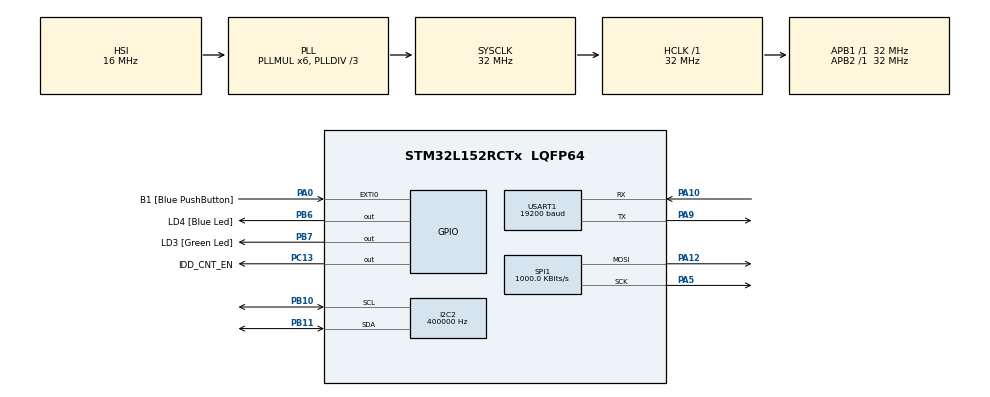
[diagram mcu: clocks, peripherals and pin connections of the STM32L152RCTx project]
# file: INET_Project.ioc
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I2C2.ClockSpeed=400000
I2C2.DutyCycle=I2C_DUTYCYCLE_2
I2C2.I2C_Mode=I2C_Fast
Mcu.Family=STM32L1
Mcu.Name=STM32L152RCTx
Mcu.Package=LQFP64
NVIC.PriorityGroup=NVIC_PRIORITYGROUP_0
PA0-WKUP1.GPIO_Label=B1 [Blue PushButton]
PA0-WKUP1.GPIO_ModeDefaultEXTI=GPIO_MODE_EVT_RISING
PA0-WKUP1.GPIO_PuPd=GPIO_NOPULL
PA0-WKUP1.Signal=GPXTI0
PA1.GPIO_Label=SEG0 [GH08172T_SEG0]
PA1.GPIO_Mode=GPIO_MODE_AF_PP
PA1.GPIO_PuPd=GPIO_NOPULL
PA1.GPIO_Speed=GPIO_SPEED_FREQ_LOW
PA1.Signal=LCD_SEG0
PA10.Mode=Asynchronous
PA10.Signal=USART1_RX
PA12.Mode=TX_Only_Simplex_Unidirect_Master
PA12.Signal=SPI1_MOSI
PA13.GPIO_Label=SWDIO
PA13.Signal=SYS_JTMS-SWDIO
PA14.GPIO_Label=SWCLK
PA14.Signal=SYS_JTCK-SWCLK
PA15.GPIO_Label=SEG12 [GH08172T_SEG12]
PA15.GPIO_Mode=GPIO_MODE_AF_PP
PA15.GPIO_PuPd=GPIO_NOPULL
PA15.GPIO_Speed=GPIO_SPEED_FREQ_LOW
PA15.Signal=LCD_SEG17
PA2.GPIO_Label=SEG1 [GH08172T_SEG1]
PA2.GPIO_Mode=GPIO_MODE_AF_PP
PA2.GPIO_PuPd=GPIO_NOPULL
PA2.GPIO_Speed=GPIO_SPEED_FREQ_LOW
PA2.Signal=LCD_SEG1
PA3.GPIO_Label=SEG2 [GH08172T_SEG2]
PA3.GPIO_Mode=GPIO_MODE_AF_PP
PA3.GPIO_PuPd=GPIO_NOPULL
PA3.GPIO_Speed=GPIO_SPEED_FREQ_LOW
PA3.Signal=LCD_SEG2
PA4.GPIO_Label=IDD_Measurement
PA4.GPIO_Mode=GPIO_MODE_ANALOG
PA4.GPIO_PuPd=GPIO_NOPULL
PA4.Signal=ADC_IN4
PA5.Mode=TX_Only_Simplex_Unidirect_Master
PA5.Signal=SPI1_SCK
PA6.GPIO_Label=GRP2_Sampling [Touch_Slider_1]
PA6.Signal=TS_G2_IO1
PA7.GPIO_Label=GRP2_Ground [Touch_Slider_1]
PA7.Signal=TS_G2_IO2
PA8.GPIO_Label=COM0 [GH08172T_COM0]
PA8.GPIO_Mode=GPIO_MODE_AF_PP
PA8.GPIO_PuPd=GPIO_NOPULL
PA8.GPIO_Speed=GPIO_SPEED_FREQ_LOW
PA8.Signal=LCD_COM0
PA9.Mode=Asynchronous
PA9.Signal=USART1_TX
PB0.GPIO_Label=GRP3_Sampling [Touch_Slider_3]
PB0.Signal=TS_G3_IO1
PB1.GPIO_Label=GRP3_Ground [Touch_Slider_3]
PB1.Signal=TS_G3_IO2
PB10.Mode=I2C
PB10.Signal=I2C2_SCL
PB11.Mode=I2C
PB11.Signal=I2C2_SDA
PB12.GPIO_Label=SEG8 [GH08172T_SEG8]
PB12.GPIO_Mode=GPIO_MODE_AF_PP
PB12.GPIO_PuPd=GPIO_NOPULL
PB12.GPIO_Speed=GPIO_SPEED_FREQ_LOW
PB12.Signal=LCD_SEG12
PB13.GPIO_Label=SEG9 [GH08172T_SEG9]
PB13.GPIO_Mode=GPIO_MODE_AF_PP
PB13.GPIO_PuPd=GPIO_NOPULL
PB13.GPIO_Speed=GPIO_SPEED_FREQ_LOW
PB13.Signal=LCD_SEG13
PB14.GPIO_Label=SEG10 [GH08172T_SEG10]
PB14.GPIO_Mode=GPIO_MODE_AF_PP
PB14.GPIO_PuPd=GPIO_NOPULL
PB14.GPIO_Speed=GPIO_SPEED_FREQ_LOW
PB14.Signal=LCD_SEG14
PB15.GPIO_Label=SEG11 [GH08172T_SEG11]
PB15.GPIO_Mode=GPIO_MODE_AF_PP
PB15.GPIO_PuPd=GPIO_NOPULL
PB15.GPIO_Speed=GPIO_SPEED_FREQ_LOW
PB15.Signal=LCD_SEG15
PB3.GPIO_Label=SEG3 [GH08172T_SEG3]
PB3.GPIO_Mode=GPIO_MODE_AF_PP
PB3.GPIO_PuPd=GPIO_NOPULL
PB3.GPIO_Speed=GPIO_SPEED_FREQ_LOW
PB3.Signal=LCD_SEG7
PB4.GPIO_Label=SEG4 [GH08172T_SEG4]
PB4.GPIO_Mode=GPIO_MODE_AF_PP
PB4.GPIO_PuPd=GPIO_NOPULL
PB4.GPIO_Speed=GPIO_SPEED_FREQ_LOW
PB4.Signal=LCD_SEG8
PB5.Signal=I2C1_SMBA
PB6.GPIO_Label=LD4 [Blue Led]
PB6.GPIO_ModeDefaultOutputPP=GPIO_MODE_OUTPUT_PP
PB6.GPIO_PuPd=GPIO_NOPULL
PB6.GPIO_Speed=GPIO_SPEED_FREQ_LOW
PB6.Signal=GPIO_Output
PB7.GPIO_Label=LD3 [Green Led]
PB7.GPIO_ModeDefaultOutputPP=GPIO_MODE_OUTPUT_PP
PB7.GPIO_PuPd=GPIO_NOPULL
PB7.GPIO_Speed=GPIO_SPEED_FREQ_LOW
PB7.Signal=GPIO_Output
PB8.GPIO_Label=SEG13 [GH08172T_SEG13]
PB8.GPIO_Mode=GPIO_MODE_AF_PP
PB8.GPIO_PuPd=GPIO_NOPULL
PB8.GPIO_Speed=GPIO_SPEED_FREQ_LOW
PB8.Signal=LCD_SEG16
PB9.GPIO_Label=COM3 [GH08172T_COM3]
PB9.GPIO_Mode=GPIO_MODE_AF_PP
PB9.GPIO_PuPd=GPIO_NOPULL
PB9.GPIO_Speed=GPIO_SPEED_FREQ_LOW
PB9.Signal=LCD_COM3
PC0.GPIO_Label=SEG14 [GH08172T_SEG14]
PC0.GPIO_Mode=GPIO_MODE_AF_PP
PC0.GPIO_PuPd=GPIO_NOPULL
PC0.GPIO_Speed=GPIO_SPEED_FREQ_LOW
PC0.Signal=LCD_SEG18
PC1.GPIO_Label=SEG15 [GH08172T_SEG15]
PC1.GPIO_Mode=GPIO_MODE_AF_PP
PC1.GPIO_PuPd=GPIO_NOPULL
PC1.GPIO_Speed=GPIO_SPEED_FREQ_LOW
PC1.Signal=LCD_SEG19
PC10.GPIO_Label=SEG22 [GH08172T_SEG22]
PC10.GPIO_Mode=GPIO_MODE_AF_PP
PC10.GPIO_PuPd=GPIO_NOPULL
PC10.GPIO_Speed=GPIO_SPEED_FREQ_LOW
PC10.Signal=LCD_SEG28
PC11.GPIO_Label=SEG23 [GH08172T_SEG23]
PC11.GPIO_Mode=GPIO_MODE_AF_PP
PC11.GPIO_PuPd=GPIO_NOPULL
PC11.GPIO_Speed=GPIO_SPEED_FREQ_LOW
PC11.Signal=LCD_SEG29
PC13-WKUP2.GPIO_Label=IDD_CNT_EN
PC13-WKUP2.Signal=GPIO_Output
PC14-OSC32_IN.GPIO_Label=PC14-OSC32_IN
PC14-OSC32_IN.Signal=RCC_OSC32_IN
PC15-OSC32_OUT.GPIO_Label=PC15-OSC32_OUT
PC15-OSC32_OUT.Signal=RCC_OSC32_OUT
PC2.GPIO_Label=SEG16 [GH08172T_SEG16]
PC2.GPIO_Mode=GPIO_MODE_AF_PP
PC2.GPIO_PuPd=GPIO_NOPULL
PC2.GPIO_Speed=GPIO_SPEED_FREQ_LOW
PC2.Signal=LCD_SEG20
PC3.GPIO_Label=SEG17 [GH08172T_SEG17]
PC3.GPIO_Mode=GPIO_MODE_AF_PP
PC3.GPIO_PuPd=GPIO_NOPULL
PC3.GPIO_Speed=GPIO_SPEED_FREQ_LOW
PC3.Signal=LCD_SEG21
PC4.GPIO_Label=GRP9_Sampling [Touch_Slider_2]
PC4.Signal=TS_G9_IO1
PC5.GPIO_Label=GRP9_Ground [Touch_Slider_2]
PC5.Signal=TS_G9_IO2
PC6.GPIO_Label=SEG18 [GH08172T_SEG18]
PC6.GPIO_Mode=GPIO_MODE_AF_PP
PC6.GPIO_PuPd=GPIO_NOPULL
PC6.GPIO_Speed=GPIO_SPEED_FREQ_LOW
PC6.Signal=LCD_SEG24
PC7.GPIO_Label=SEG19 [GH08172T_SEG19]
PC7.GPIO_Mode=GPIO_MODE_AF_PP
PC7.GPIO_PuPd=GPIO_NOPULL
PC7.GPIO_Speed=GPIO_SPEED_FREQ_LOW
PC7.Signal=LCD_SEG25
PC8.GPIO_Label=SEG20 [GH08172T_SEG20]
PC8.GPIO_Mode=GPIO_MODE_AF_PP
PC8.GPIO_PuPd=GPIO_NOPULL
PC8.GPIO_Speed=GPIO_SPEED_FREQ_LOW
PC8.Signal=LCD_SEG26
PC9.GPIO_Label=SEG21 [GH08172T_SEG21]
PC9.GPIO_Mode=GPIO_MODE_AF_PP
PC9.GPIO_PuPd=GPIO_NOPULL
PC9.GPIO_Speed=GPIO_SPEED_FREQ_LOW
PC9.Signal=LCD_SEG27
ProjectManager.HeapSize=0x200
ProjectManager.StackSize=0x400
ProjectManager.TargetToolchain=MDK-ARM V5
RCC.AHBFreq_Value=32000000
RCC.APB1Freq_Value=32000000
RCC.APB1TimFreq_Value=32000000
RCC.APB2Freq_Value=32000000
RCC.APB2TimFreq_Value=32000000
RCC.HCLKFreq_Value=32000000
RCC.HSE_VALUE=8000000
RCC.HSI_VALUE=16000000
RCC.LSE_VALUE=32768
RCC.MSI_VALUE=2097000
RCC.PLLDIV=RCC_PLL_DIV3
RCC.PLLMUL=RCC_PLL_MUL6
RCC.RTCClockSelectionVirtual=RCC_RTCCLKSOURCE_LSE
RCC.SYSCLKFreq_VALUE=32000000
RCC.SYSCLKSource=RCC_SYSCLKSOURCE_PLLCLK
RCC.USBOutput=48000000
RCC.VCOOutputFreq_Value=96000000
SPI1.BaudRatePrescaler=SPI_BAUDRATEPRESCALER_32
SPI1.CLKPolarity=SPI_POLARITY_HIGH
SPI1.CalculateBaudRate=1000.0 KBits/s
SPI1.Mode=SPI_MODE_MASTER
USART1.BaudRate=19200
board=STM32L152C-DISCO

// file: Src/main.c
/**
  ******************************************************************************
  * File Name          : main.c
  * Description        : Main program body
  ******************************************************************************
  *
  * COPYRIGHT(c) 2017 STMicroelectronics
  *
  * Redistribution and use in source and binary forms, with or without modification,
  * are permitted provided that the following conditions are met:
  *   1. Redistributions of source code must retain the above copyright notice,
  *      this list of conditions and the following disclaimer.
  *   2. Redistributions in binary form must reproduce the above copyright notice,
  *      this list of conditions and the following disclaimer in the documentation
  *      and/or other materials provided with the distribution.
  *   3. Neither the name of STMicroelectronics nor the names of its contributors
  *      may be used to endorse or promote products derived from this software
  *      without specific prior written permission.
  *
  * THIS SOFTWARE IS PROVIDED BY THE COPYRIGHT HOLDERS AND CONTRIBUTORS "AS IS"
  * AND ANY EXPRESS OR IMPLIED WARRANTIES, INCLUDING, BUT NOT LIMITED TO, THE
  * IMPLIED WARRANTIES OF MERCHANTABILITY AND FITNESS FOR A PARTICULAR PURPOSE ARE
  * DISCLAIMED. IN NO EVENT SHALL THE COPYRIGHT HOLDER OR CONTRIBUTORS BE LIABLE
  * FOR ANY DIRECT, INDIRECT, INCIDENTAL, SPECIAL, EXEMPLARY, OR CONSEQUENTIAL
  * DAMAGES (INCLUDING, BUT NOT LIMITED TO, PROCUREMENT OF SUBSTITUTE GOODS OR
  * SERVICES; LOSS OF USE, DATA, OR PROFITS; OR BUSINESS INTERRUPTION) HOWEVER
  * CAUSED AND ON ANY THEORY OF LIABILITY, WHETHER IN CONTRACT, STRICT LIABILITY,
  * OR TORT (INCLUDING NEGLIGENCE OR OTHERWISE) ARISING IN ANY WAY OUT OF THE USE
  * OF THIS SOFTWARE, EVEN IF ADVISED OF THE POSSIBILITY OF SUCH DAMAGE.
  *
  ******************************************************************************
  */
#include "stm32l1xx_hal.h"

/* USER CODE BEGIN Includes */
#include <string.h>
/* USER CODE END Includes */

I2C_HandleTypeDef hi2c2;

SPI_HandleTypeDef hspi1;

UART_HandleTypeDef huart1;

/* USER CODE BEGIN PV */
/* Private variables ---------------------------------------------------------*/

/* USER CODE END PV */

void SystemClock_Config(void);
void Error_Handler(void);
static void MX_GPIO_Init(void);
static void MX_I2C2_Init(void);
static void MX_SPI1_Init(void);
static void MX_USART1_UART_Init(void);

/* USER CODE BEGIN PFP */
/* Private function prototypes -----------------------------------------------*/

/* USER CODE END PFP */

/* USER CODE BEGIN 0 */
uint8_t strHolaMundo[] = "HOLA MUNDO";
const uint16_t cAddressAT93C86A = 0x51;
/* USER CODE END 0 */

int main(void)
{

  /* MCU Configuration----------------------------------------------------------*/

  /* Reset of all peripherals, Initializes the Flash interface and the Systick. */
  HAL_Init();

  /* Configure the system clock */
  SystemClock_Config();

  /* Initialize all configured peripherals */
  MX_GPIO_Init();
  MX_I2C2_Init();
  MX_SPI1_Init();
  MX_USART1_UART_Init();

  /* Infinite loop */
  while (1)
  {

  /* USER CODE BEGIN 3 */
		HAL_UART_Transmit(&huart1,strHolaMundo,strlen((char *)strHolaMundo),100);
		HAL_Delay(100);

		HAL_I2C_Master_Transmit(&hi2c2,cAddressAT93C86A,strHolaMundo,strlen((char *)strHolaMundo),100);
		HAL_Delay(100);

		HAL_SPI_Transmit(&hspi1,strHolaMundo,strlen((char *)strHolaMundo),100);
		HAL_Delay(100);

  }
  /* USER CODE END 3 */

}

/** System Clock Configuration
*/
void SystemClock_Config(void)
{

  RCC_OscInitTypeDef RCC_OscInitStruct;
  RCC_ClkInitTypeDef RCC_ClkInitStruct;

  __HAL_RCC_PWR_CLK_ENABLE();

  __HAL_PWR_VOLTAGESCALING_CONFIG(PWR_REGULATOR_VOLTAGE_SCALE1);

  RCC_OscInitStruct.OscillatorType = RCC_OSCILLATORTYPE_HSI;
  RCC_OscInitStruct.HSIState = RCC_HSI_ON;
  RCC_OscInitStruct.HSICalibrationValue = 16;
  RCC_OscInitStruct.PLL.PLLState = RCC_PLL_ON;
  RCC_OscInitStruct.PLL.PLLSource = RCC_PLLSOURCE_HSI;
  RCC_OscInitStruct.PLL.PLLMUL = RCC_PLL_MUL6;
  RCC_OscInitStruct.PLL.PLLDIV = RCC_PLL_DIV3;
  if (HAL_RCC_OscConfig(&RCC_OscInitStruct) != HAL_OK)
  {
    Error_Handler();
  }

  RCC_ClkInitStruct.ClockType = RCC_CLOCKTYPE_HCLK|RCC_CLOCKTYPE_SYSCLK
                              |RCC_CLOCKTYPE_PCLK1|RCC_CLOCKTYPE_PCLK2;
  RCC_ClkInitStruct.SYSCLKSource = RCC_SYSCLKSOURCE_PLLCLK;
  RCC_ClkInitStruct.AHBCLKDivider = RCC_SYSCLK_DIV1;
  RCC_ClkInitStruct.APB1CLKDivider = RCC_HCLK_DIV1;
  RCC_ClkInitStruct.APB2CLKDivider = RCC_HCLK_DIV1;
  if (HAL_RCC_ClockConfig(&RCC_ClkInitStruct, FLASH_LATENCY_1) != HAL_OK)
  {
    Error_Handler();
  }

  HAL_SYSTICK_Config(HAL_RCC_GetHCLKFreq()/1000);

  HAL_SYSTICK_CLKSourceConfig(SYSTICK_CLKSOURCE_HCLK);

  /* SysTick_IRQn interrupt configuration */
  HAL_NVIC_SetPriority(SysTick_IRQn, 0, 0);
}

/* I2C2 init function */
static void MX_I2C2_Init(void)
{

  hi2c2.Instance = I2C2;
  hi2c2.Init.ClockSpeed = 400000;
  hi2c2.Init.DutyCycle = I2C_DUTYCYCLE_2;
  hi2c2.Init.OwnAddress1 = 0;
  hi2c2.Init.AddressingMode = I2C_ADDRESSINGMODE_7BIT;
  hi2c2.Init.DualAddressMode = I2C_DUALADDRESS_DISABLE;
  hi2c2.Init.OwnAddress2 = 0;
  hi2c2.Init.GeneralCallMode = I2C_GENERALCALL_DISABLE;
  hi2c2.Init.NoStretchMode = I2C_NOSTRETCH_DISABLE;
  if (HAL_I2C_Init(&hi2c2) != HAL_OK)
  {
    Error_Handler();
  }

}

/* SPI1 init function */
static void MX_SPI1_Init(void)
{

  hspi1.Instance = SPI1;
  hspi1.Init.Mode = SPI_MODE_MASTER;
  hspi1.Init.Direction = SPI_DIRECTION_2LINES;
  hspi1.Init.DataSize = SPI_DATASIZE_8BIT;
  hspi1.Init.CLKPolarity = SPI_POLARITY_HIGH;
  hspi1.Init.CLKPhase = SPI_PHASE_1EDGE;
  hspi1.Init.NSS = SPI_NSS_SOFT;
  hspi1.Init.BaudRatePrescaler = SPI_BAUDRATEPRESCALER_32;
  hspi1.Init.FirstBit = SPI_FIRSTBIT_MSB;
  hspi1.Init.TIMode = SPI_TIMODE_DISABLE;
  hspi1.Init.CRCCalculation = SPI_CRCCALCULATION_DISABLE;
  hspi1.Init.CRCPolynomial = 10;
  if (HAL_SPI_Init(&hspi1) != HAL_OK)
  {
    Error_Handler();
  }

}

/* USART1 init function */
static void MX_USART1_UART_Init(void)
{

  huart1.Instance = USART1;
  huart1.Init.BaudRate = 19200;
  huart1.Init.WordLength = UART_WORDLENGTH_8B;
  huart1.Init.StopBits = UART_STOPBITS_1;
  huart1.Init.Parity = UART_PARITY_NONE;
  huart1.Init.Mode = UART_MODE_TX_RX;
  huart1.Init.HwFlowCtl = UART_HWCONTROL_NONE;
  huart1.Init.OverSampling = UART_OVERSAMPLING_16;
  if (HAL_UART_Init(&huart1) != HAL_OK)
  {
    Error_Handler();
  }

}

/** Configure pins as
        * Analog
        * Input
        * Output
        * EVENT_OUT
        * EXTI
     PC0   ------> LCD_SEG18
     PC1   ------> LCD_SEG19
     PC2   ------> LCD_SEG20
     PC3   ------> LCD_SEG21
     PA1   ------> LCD_SEG0
     PA2   ------> LCD_SEG1
     PA3   ------> LCD_SEG2
     PA4   ------> ADC_IN4
     PA6   ------> TS_G2_IO1
     PA7   ------> TS_G2_IO2
     PC4   ------> TS_G9_IO1
     PC5   ------> TS_G9_IO2
     PB0   ------> TS_G3_IO1
     PB1   ------> TS_G3_IO2
     PB12   ------> LCD_SEG12
     PB13   ------> LCD_SEG13
     PB14   ------> LCD_SEG14
     PB15   ------> LCD_SEG15
     PC6   ------> LCD_SEG24
     PC7   ------> LCD_SEG25
     PC8   ------> LCD_SEG26
     PC9   ------> LCD_SEG27
     PA8   ------> LCD_COM0
     PA15   ------> LCD_SEG17
     PC10   ------> LCD_SEG28
     PC11   ------> LCD_SEG29
     PB3   ------> LCD_SEG7
     PB4   ------> LCD_SEG8
     PB5   ------> I2C1_SMBA
     PB8   ------> LCD_SEG16
     PB9   ------> LCD_COM3
*/
static void MX_GPIO_Init(void)
{

  GPIO_InitTypeDef GPIO_InitStruct;

  /* GPIO Ports Clock Enable */
  __HAL_RCC_GPIOC_CLK_ENABLE();
  __HAL_RCC_GPIOA_CLK_ENABLE();
  __HAL_RCC_GPIOB_CLK_ENABLE();

  /*Configure GPIO pin Output Level */
  HAL_GPIO_WritePin(IDD_CNT_EN_GPIO_Port, IDD_CNT_EN_Pin, GPIO_PIN_RESET);

  /*Configure GPIO pin Output Level */
  HAL_GPIO_WritePin(GPIOB, LD4_Pin|LD3_Pin, GPIO_PIN_RESET);

  /*Configure GPIO pin : IDD_CNT_EN_Pin */
  GPIO_InitStruct.Pin = IDD_CNT_EN_Pin;
  GPIO_InitStruct.Mode = GPIO_MODE_OUTPUT_PP;
  GPIO_InitStruct.Pull = GPIO_NOPULL;
  GPIO_InitStruct.Speed = GPIO_SPEED_FREQ_LOW;
  HAL_GPIO_Init(IDD_CNT_EN_GPIO_Port, &GPIO_InitStruct);

  /*Configure GPIO pins : SEG14_Pin SEG15_Pin SEG16_Pin SEG17_Pin
                           SEG18_Pin SEG19_Pin SEG20_Pin SEG21_Pin
                           SEG22_Pin SEG23_Pin */
  GPIO_InitStruct.Pin = SEG14_Pin|SEG15_Pin|SEG16_Pin|SEG17_Pin
                          |SEG18_Pin|SEG19_Pin|SEG20_Pin|SEG21_Pin
                          |SEG22_Pin|SEG23_Pin;
  GPIO_InitStruct.Mode = GPIO_MODE_AF_PP;
  GPIO_InitStruct.Pull = GPIO_NOPULL;
  GPIO_InitStruct.Speed = GPIO_SPEED_FREQ_LOW;
  GPIO_InitStruct.Alternate = GPIO_AF11_LCD;
  HAL_GPIO_Init(GPIOC, &GPIO_InitStruct);

  /*Configure GPIO pin : B1_Pin */
  GPIO_InitStruct.Pin = B1_Pin;
  GPIO_InitStruct.Mode = GPIO_MODE_EVT_RISING;
  GPIO_InitStruct.Pull = GPIO_NOPULL;
  HAL_GPIO_Init(B1_GPIO_Port, &GPIO_InitStruct);

  /*Configure GPIO pins : SEG0_Pin SEG1_Pin SEG2_Pin COM0_Pin
                           SEG12_Pin */
  GPIO_InitStruct.Pin = SEG0_Pin|SEG1_Pin|SEG2_Pin|COM0_Pin
                          |SEG12_Pin;
  GPIO_InitStruct.Mode = GPIO_MODE_AF_PP;
  GPIO_InitStruct.Pull = GPIO_NOPULL;
  GPIO_InitStruct.Speed = GPIO_SPEED_FREQ_LOW;
  GPIO_InitStruct.Alternate = GPIO_AF11_LCD;
  HAL_GPIO_Init(GPIOA, &GPIO_InitStruct);

  /*Configure GPIO pin : IDD_Measurement_Pin */
  GPIO_InitStruct.Pin = IDD_Measurement_Pin;
  GPIO_InitStruct.Mode = GPIO_MODE_ANALOG;
  GPIO_InitStruct.Pull = GPIO_NOPULL;
  HAL_GPIO_Init(IDD_Measurement_GPIO_Port, &GPIO_InitStruct);

  /*Configure GPIO pins : GRP2_Sampling_Pin GRP2_Ground_Pin */
  GPIO_InitStruct.Pin = GRP2_Sampling_Pin|GRP2_Ground_Pin;
  GPIO_InitStruct.Mode = GPIO_MODE_ANALOG;
  GPIO_InitStruct.Pull = GPIO_NOPULL;
  HAL_GPIO_Init(GPIOA, &GPIO_InitStruct);

  /*Configure GPIO pins : GRP9_Sampling_Pin GRP9_Ground_Pin */
  GPIO_InitStruct.Pin = GRP9_Sampling_Pin|GRP9_Ground_Pin;
  GPIO_InitStruct.Mode = GPIO_MODE_ANALOG;
  GPIO_InitStruct.Pull = GPIO_NOPULL;
  HAL_GPIO_Init(GPIOC, &GPIO_InitStruct);

  /*Configure GPIO pins : GRP3_Sampling_Pin GRP3_Ground_Pin */
  GPIO_InitStruct.Pin = GRP3_Sampling_Pin|GRP3_Ground_Pin;
  GPIO_InitStruct.Mode = GPIO_MODE_ANALOG;
  GPIO_InitStruct.Pull = GPIO_NOPULL;
  HAL_GPIO_Init(GPIOB, &GPIO_InitStruct);

  /*Configure GPIO pins : SEG8_Pin SEG9_Pin SEG10_Pin SEG11_Pin
                           SEG3_Pin SEG4_Pin SEG13_Pin COM3_Pin */
  GPIO_InitStruct.Pin = SEG8_Pin|SEG9_Pin|SEG10_Pin|SEG11_Pin
                          |SEG3_Pin|SEG4_Pin|SEG13_Pin|COM3_Pin;
  GPIO_InitStruct.Mode = GPIO_MODE_AF_PP;
  GPIO_InitStruct.Pull = GPIO_NOPULL;
  GPIO_InitStruct.Speed = GPIO_SPEED_FREQ_LOW;
  GPIO_InitStruct.Alternate = GPIO_AF11_LCD;
  HAL_GPIO_Init(GPIOB, &GPIO_InitStruct);

  /*Configure GPIO pin : PB5 */
  GPIO_InitStruct.Pin = GPIO_PIN_5;
  GPIO_InitStruct.Mode = GPIO_MODE_AF_OD;
  GPIO_InitStruct.Pull = GPIO_PULLUP;
  GPIO_InitStruct.Speed = GPIO_SPEED_FREQ_VERY_HIGH;
  GPIO_InitStruct.Alternate = GPIO_AF4_I2C1;
  HAL_GPIO_Init(GPIOB, &GPIO_InitStruct);

  /*Configure GPIO pins : LD4_Pin LD3_Pin */
  GPIO_InitStruct.Pin = LD4_Pin|LD3_Pin;
  GPIO_InitStruct.Mode = GPIO_MODE_OUTPUT_PP;
  GPIO_InitStruct.Pull = GPIO_NOPULL;
  GPIO_InitStruct.Speed = GPIO_SPEED_FREQ_LOW;
  HAL_GPIO_Init(GPIOB, &GPIO_InitStruct);

}

void Error_Handler(void)
{
  while(1)
  {
  }
}

/************************ (C) COPYRIGHT STMicroelectronics *****END OF FILE****/
